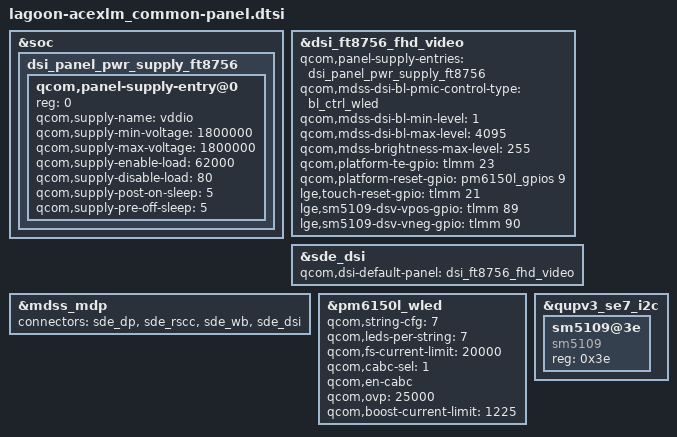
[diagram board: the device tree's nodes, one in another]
// SPDX-License-Identifier: GPL-2.0-only
/*
 * Copyright (c) 2018-2019, The Linux Foundation. All rights reserved.
 */

#include "dsi-panel-ft8756-tcl-fhd-video.dtsi"

&soc {
/*
	panel_vsp_ldo: panel_ldo-gpio-vsp-regulator {
		compatible = "regulator-fixed";

		regulator-name = "panel_ldo-gpio-vsp-supply";
		regulator-min-microvolt = <1800000>;
		regulator-max-microvolt = <1800000>;

		gpio = <&tlmm 89 0>;
		enable-active-high;
		regulator-boot-on;
	};
	panel_vsn_ldo: panel_ldo-gpio-vsn-regulator {
		compatible = "regulator-fixed";

		regulator-name = "panel_ldo-gpio-vsn-supply";
		regulator-min-microvolt = <1800000>;
		regulator-max-microvolt = <1800000>;

		gpio = <&tlmm 90 0>;
		enable-active-high;
		regulator-boot-on;
	};
*/
	dsi_panel_pwr_supply_ft8756: dsi_panel_pwr_supply_ft8756 {
		#address-cells = <1>;
		#size-cells = <0>;

		qcom,panel-supply-entry@0 {
			reg = <0>;
			qcom,supply-name = "vddio";
			qcom,supply-min-voltage = <1800000>;
			qcom,supply-max-voltage = <1800000>;
			qcom,supply-enable-load = <62000>;
			qcom,supply-disable-load = <80>;
			qcom,supply-post-on-sleep = <5>;
			qcom,supply-pre-off-sleep = <5>;
		};

/*
        qcom,panel-supply-entry@1 {
			reg = <1>;
			qcom,supply-name = "panel_vsp_ldo";
			qcom,supply-min-voltage = <1800000>;
			qcom,supply-max-voltage = <1800000>;
			qcom,supply-enable-load = <62000>;
			qcom,supply-disable-load = <80>;
			qcom,supply-post-on-sleep = <7>;
		};

        qcom,panel-supply-entry@2 {
			reg = <2>;
			qcom,supply-name = "panel_vsn_ldo";
			qcom,supply-min-voltage = <1800000>;
			qcom,supply-max-voltage = <1800000>;
			qcom,supply-enable-load = <62000>;
			qcom,supply-disable-load = <80>;
			qcom,supply-post-on-sleep = <5>;
			qcom,supply-pre-off-sleep = <5>;
		};
*/
	};
};

&dsi_ft8756_fhd_video {
	qcom,panel-supply-entries = <&dsi_panel_pwr_supply_ft8756>;
	qcom,mdss-dsi-bl-pmic-control-type = "bl_ctrl_wled";
	qcom,mdss-dsi-bl-min-level = <1>;
	qcom,mdss-dsi-bl-max-level = <4095>;
	qcom,mdss-brightness-max-level = <255>;
	qcom,platform-te-gpio = <&tlmm 23 0>;
	qcom,platform-reset-gpio = <&pm6150l_gpios 9 0>;
	lge,touch-reset-gpio = <&tlmm 21 0>;
	lge,sm5109-dsv-vpos-gpio = <&tlmm 89 0>;
	lge,sm5109-dsv-vneg-gpio = <&tlmm 90 0>;
};

 &sde_dsi {
	qcom,dsi-default-panel = <&dsi_ft8756_fhd_video>;
//	panel_vsp_ldo-supply = <&panel_vsp_ldo>;
//	panel_vsn_ldo-supply = <&panel_vsn_ldo>;
 };

&mdss_mdp {
	connectors = <&sde_dp &sde_rscc &sde_wb &sde_dsi>;
};

&pm6150l_wled {
	qcom,string-cfg= <7>;
	qcom,leds-per-string = <7>;
	qcom,fs-current-limit = <20000>;
	qcom,cabc-sel = <1>;
	qcom,en-cabc;
	qcom,ovp = <25000>;
	qcom,boost-current-limit = <1225>;
	status = "ok";
};

&qupv3_se7_i2c {
	sm5109@3e {
		compatible = "sm5109";
		status="okay";
		reg = <0x3e>;
	};
};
